# TPCC0_TPCC0 register map
Vendor: Texas Instruments
Peripheral module from a debugger description file (folder AM263).
Registers are 32-bit, read-only, reset 0x0 unless marked. A register's access mark holds for its fields unless they carry their own. Offsets are as the file gives them; lines under a group give offsets from that group; [hi:lo] are bit positions; {n}, {i} and the like mark numbered series; 'fields as' and 'values as' point back to an identical list; <NAME> marks a mode.

## TPCC0_TPCC0
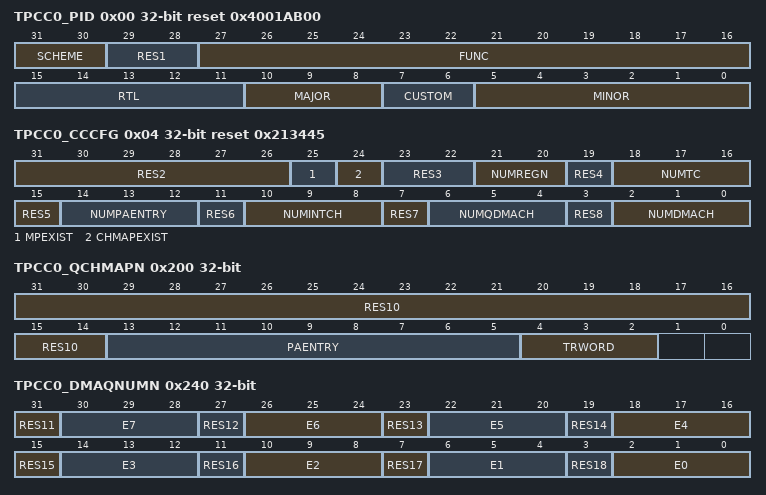
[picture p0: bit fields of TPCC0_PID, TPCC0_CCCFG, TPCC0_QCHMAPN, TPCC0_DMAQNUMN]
0x00 TPCC0_PID reset 0x4001AB00
  [31:30] SCHEME — PID Scheme: Used to distinguish between old ID scheme and current. Spare bit to encode future schemes EDMA uses 'new scheme' indicated with value of 0x1.
  [29:28] RES1 — RESERVE FIELD
  [27:16] FUNC — Function indicates a software compatible module family.
  [15:11] RTL — RTL Version
  [10:8] MAJOR — Major Revision
  [7:6] CUSTOM — Custom revision field: Not used on this version of EDMA.
  [5:0] MINOR — Minor Revision
0x04 TPCC0_CCCFG reset 0x213445
  [31:26] RES2 — RESERVE FIELD
  [25] MPEXIST — Memory Protection Existence MPEXIST = 0 : No memory protection. MPEXIST = 1 : Memory Protection logic included.
  [24] CHMAPEXIST — Channel Mapping Existence CHMAPEXIST = 0 : No Channel mapping. CHMAPEXIST = 1 : Channel mapping logic included.
  [23:22] RES3 — RESERVE FIELD
  [21:20] NUMREGN — Number of MP and Shadow regions
  [35-4n] RES{n} (n=4..8) — RESERVE FIELD
  [18:16] NUMTC — Number of Queues/Number of TCs
  [14:12] NUMPAENTRY — Number of PaRAM entries
  [10:8] NUMINTCH — Number of Interrupt Channels
  [6:4] NUMQDMACH — Number of QDMA Channels
  [2:0] NUMDMACH — Number of DMA Channels
0x200 TPCC0_QCHMAPN access per field
  [31:14] RES10 ro — RESERVE FIELD
  [13:5] PAENTRY rw — PaRAM Entry number for QDMA Channel N.
  [4:2] TRWORD rw — TRWORD points to the specific trigger word of the PaRAM Entry defined by PAENTRY. A write to the trigger word results in a QDMA Event being recognized.
0x240 TPCC0_DMAQNUMN access per field
  [75-4n] RES{n} ro (n=11..18) — RESERVE FIELD
  [4n+2:4n] E{n} rw (n=0..7) — DMA Queue Number for event #{n}
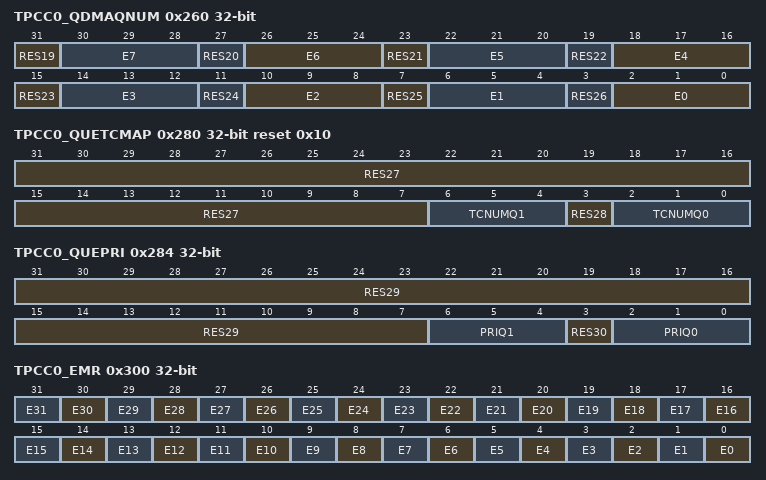
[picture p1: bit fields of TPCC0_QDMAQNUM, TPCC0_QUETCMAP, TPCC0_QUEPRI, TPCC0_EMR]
0x260 TPCC0_QDMAQNUM access per field
  [107-4n] RES{n} ro (n=19..26) — RESERVE FIELD
  [4n+2:4n] E{n} rw (n=0..7) — QDMA Queue Number for event #{n}
0x280 TPCC0_QUETCMAP access per field reset 0x10
  [31:7] RES27 ro — RESERVE FIELD
  [6:4] TCNUMQ1 rw — TC Number for Queue N: Defines the TC number that Event Queue N TRs are written to.
  [3] RES28 ro — RESERVE FIELD
  [2:0] TCNUMQ0 rw — TC Number for Queue N: Defines the TC number that Event Queue N TRs are written to.
0x284 TPCC0_QUEPRI access per field
  [31:7] RES29 ro — RESERVE FIELD
  [6:4] PRIQ1 rw — Priority Level for Queue 1 Dictates the priority level used for the OPTIONS field programmation for Qn TRs. Sets the priority used for TC read and write commands.
  [3] RES30 ro — RESERVE FIELD
  [2:0] PRIQ0 rw — Priority Level for Queue 0 Dictates the priority level used for the OPTIONS field programmation for Qn TRs. Sets the priority used for TC read and write commands.
0x300 TPCC0_EMR
  [n] E{n} (n=0..31) — Event Missed #{n}
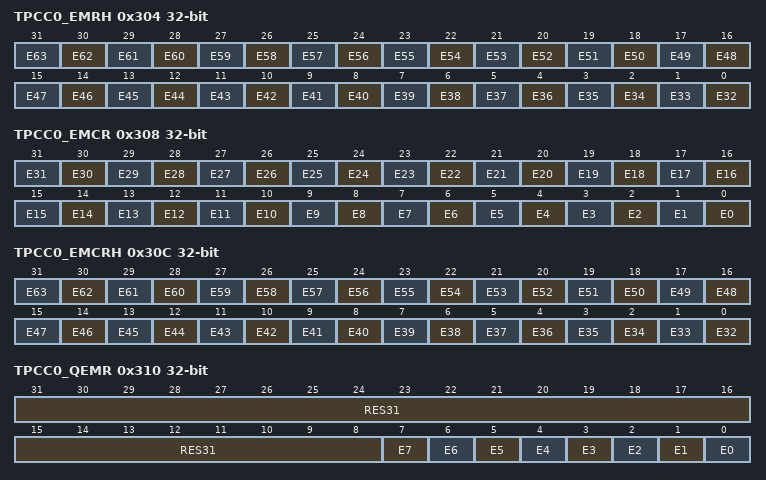
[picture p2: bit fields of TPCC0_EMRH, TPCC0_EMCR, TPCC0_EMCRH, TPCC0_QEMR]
0x304 TPCC0_EMRH
  [n-32] E{n} (n=32..63) — Event Missed #{n}
0x308 TPCC0_EMCR wo
  [n] E{n} (n=0..31) — Event Missed Clear #{n}
0x30C TPCC0_EMCRH wo
  [n-32] E{n} (n=32..63) — Event Missed Clear #{n}
0x310 TPCC0_QEMR
  [31:8] RES31 — RESERVE FIELD
  [n] E{n} (n=0..7) — Event Missed #{n}
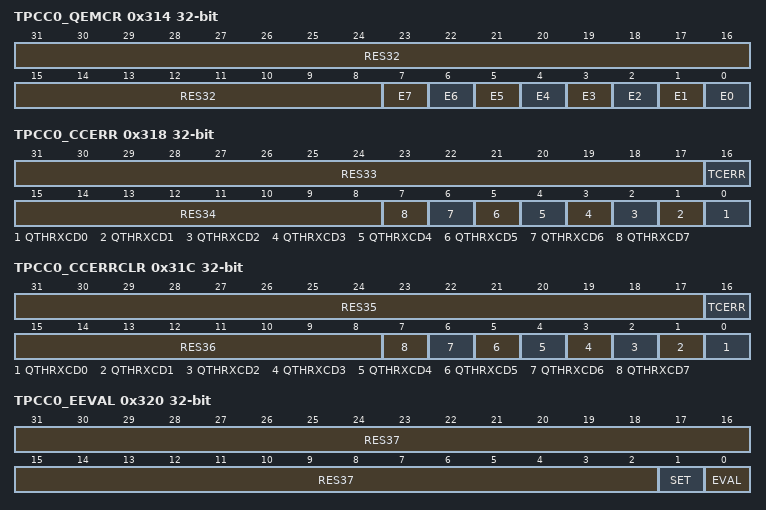
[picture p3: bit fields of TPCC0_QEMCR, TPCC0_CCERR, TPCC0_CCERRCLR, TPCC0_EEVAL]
0x314 TPCC0_QEMCR access per field
  [31:8] RES32 ro — RESERVE FIELD
  [n] E{n} wo (n=0..7) — Event Missed Clear #{n}
0x318 TPCC0_CCERR
  [31:17] RES33 — RESERVE FIELD
  [16] TCERR — Transfer Completion Code Error: TCCERR = 0 : Total number of allowed TCCs outstanding has not been reached. TCCERR = 1 : Total number of allowed TCCs has been reached. TCCERR can be cleared by writing a '1' to corresponding bit in CCERRCLR register. If any bit in the CCERR register is set (and all errors were previously clear) then an error will be signaled with TPCC error interrupt.
  [15:8] RES34 — RESERVE FIELD
  [n] QTHRXCD{n} (n=0..7) — Queue Threshold Error for Q{n}: QTHRXCD{n} = 0 : Watermark/threshold has not been exceeded. QTHRXCD{n} = 1 : Watermark/threshold has been exceeded. CCERR.QTHRXCD{n} can be cleared by writing a '1' to corresponding bit in CCERRCLR register. If any bit in the CCERR register is set (and all errors (including EMR/QEMR) were previously clear) then an error will be signaled with the TPCC error interrupt.
0x31C TPCC0_CCERRCLR access per field
  [31:17] RES35 ro — RESERVE FIELD
  [16] TCERR wo — Clear Error for CCERR.TCERR: Write of '1' clears the value of CCERR bit N. Writes of '0' have no affect.
  [15:8] RES36 ro — RESERVE FIELD
  [n] QTHRXCD{n} wo (n=0..7) — Clear error for CCERR.QTHRXCD{n}: Write of '1' clears the values of QSTAT{n}.WM QSTAT{n}.THRXCD CCERR.QTHRXCD{n} Writes of '0' have no affect.
0x320 TPCC0_EEVAL access per field
  [31:2] RES37 ro — RESERVE FIELD
  [1] SET wo — Error Interrupt Set: CPU write of '1' to the SET bit causes the TPCC error interrupt to be pulsed regardless of state of EMR/EMRH QEMR or CCERR. CPU write of '0' has no effect.
  [0] EVAL wo — Error Interrupt Evaluate: CPU write of '1' to the EVAL bit causes the TPCC error interrupt to be pulsed if any errors have not been cleared in the EMR/EMRH QEMR or CCERR registers. CPU write of '0' has no effect.
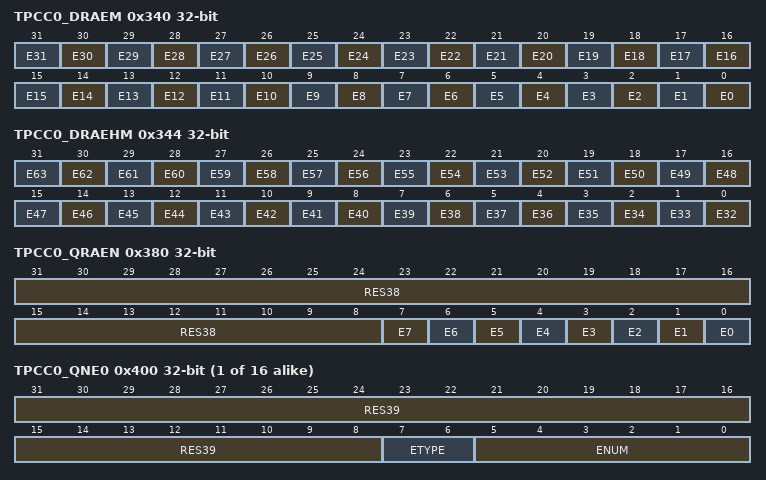
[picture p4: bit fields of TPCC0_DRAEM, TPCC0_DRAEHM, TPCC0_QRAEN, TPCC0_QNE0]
0x340 TPCC0_DRAEM rw
  [n] E{n} (n=0..31) — DMA Region Access enable for Region M bit #{n}
0x344 TPCC0_DRAEHM rw
  [n-32] E{n} (n=32..63) — DMA Region Access enable for Region M bit #{n}
0x380 TPCC0_QRAEN access per field
  [31:8] RES38 ro — RESERVE FIELD
  [n] E{n} rw (n=0..7) — QDMA Region Access enable for Region M bit #{n}
{0x400+4i} TPCC0_QNE{i} (i=0..15)
  [31:8] RES{i+39} — RESERVE FIELD
  [7:6] ETYPE — Event Type: Specifies the specific Event Type for the given entry in the Event Queue.
  [5:0] ENUM — Event Number: Specifies the specific Event Number for the given entry in the Event Queue. For DMA Channel events (ER/ESR/CER) ENUM will range between 0 and NUM_DMACH (up to 63). For QDMA Channel events (QER) ENUM will range between 0 and NUM_QDMACH (up to 7).
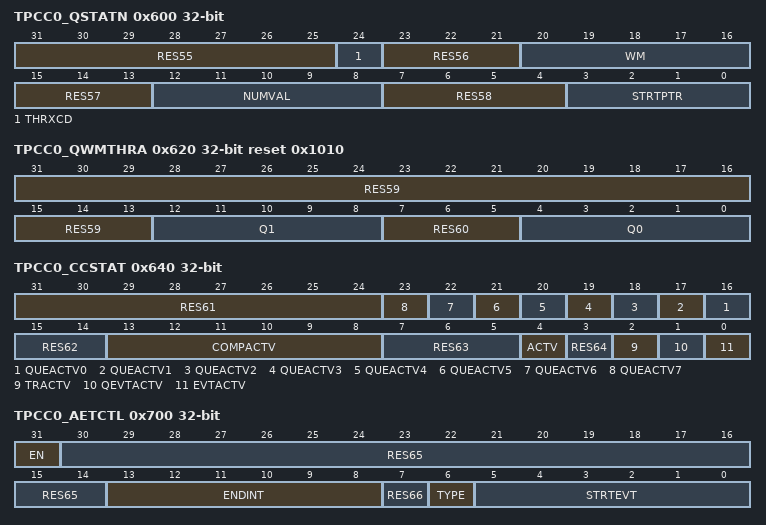
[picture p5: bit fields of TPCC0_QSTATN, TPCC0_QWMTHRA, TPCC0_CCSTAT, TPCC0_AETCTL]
0x600 TPCC0_QSTATN
  [31:25] RES55 — RESERVE FIELD
  [24] THRXCD — Threshold Exceeded: THRXCD = 0 : Threshold specified by QWMTHR(A B).Qn has not been exceeded. THRXCD = 1 : Threshold specified by QWMTHR(A B).Qn has been exceeded. QSTATn.THRXCD is cleared via CCERR.WMCLRn bit.
  [23:21] RES56 — RESERVE FIELD
  [20:16] WM — Watermark for Maximum Queue Usage: Watermark tracks the most entries that have been in QueueN since reset or since the last time that the watermark (WM) was cleared. QSTATn.WM is cleared via CCERR.WMCLRn bit. Legal values = 0x0 (empty) to 0x10 (full)
  [15:13] RES57 — RESERVE FIELD
  [12:8] NUMVAL — Number of Valid Entries in QueueN: Represents the total number of entries residing in the Queue Manager FIFO at a given instant. Always enabled. Legal values = 0x0 (empty) to 0x10 (full)
  [7:4] RES58 — RESERVE FIELD
  [3:0] STRTPTR — Start Pointer: Represents the offset to the head entry of QueueN in units of entries. Always enabled. Legal values = 0x0 (0th entry) to 0xF (15th entry)
0x620 TPCC0_QWMTHRA access per field reset 0x1010
  [31:13] RES59 ro — RESERVE FIELD
  [12:8] Q1 rw — Queue Threshold for Q1 value
  [7:5] RES60 ro — RESERVE FIELD
  [4:0] Q0 rw — Queue Threshold for Q0 value
0x640 TPCC0_CCSTAT
  [31:24] RES61 — RESERVE FIELD
  [n+16] QUEACTV{n} (n=0..7) — Queue {n} Active QUEACTV{n} = 0 : No Evts are queued in Q{n}. QUEACTV{n} = 1 : At least one TR is queued in Q{n}.
  [15:14] RES62 — RESERVE FIELD
  [13:8] COMPACTV — Completion Request Active: Counter that tracks the total number of completion requests submitted to the TC. The counter increments when a TR is submitted with TCINTEN or TCCHEN set to '1'. The counter decrements for every valid completion code received from any of the external TCs. The CC will not service new TRs if COMPACTV count is already at the limit. COMPACTV = 0 : No completion requests outstanding. COMPACTV = 1: Total of '1' completion request outstanding. ... COMPACTV = 63 : Total of 63 completion requests are outstanding. No additional TRs will be submitted until count is less than 63.
  [7:5] RES63 — RESERVE FIELD
  [4] ACTV — Channel Controller Active: Channel Controller Active is a logical-OR of each of the ACTV signals. The ACTV bit must remain high through the life of a TR. ACTV = 0 : Channel is idle. ACTV = 1 : Channel is busy.
  [3] RES64 — RESERVE FIELD
  [2] TRACTV — Transfer Request Active: TRACTV = 0 : Transfer Request processing/submission logic is inactive. TRACTV = 1 : Transfer Request processing/submission logic is active.
  [1] QEVTACTV — QDMA Event Active: QEVTACTV = 0 : No enabled QDMA Events are active within the CC. QEVTACTV = 1 : At least one enabled DMA Event (ER & EER ESR CER) is active within the CC.
  [0] EVTACTV — DMA Event Active: EVTACTV = 0 : No enabled DMA Events are active within the CC. EVTACTV = 1 : At least one enabled DMA Event (ER & EER ESR CER) is active within the CC.
0x700 TPCC0_AETCTL access per field
  [31] EN rw — AET Enable: EN = 0 : AET event generation is disabled. EN = 1 : AET event generation is enabled.
  [30:14] RES65 ro — RESERVE FIELD
  [13:8] ENDINT rw — AET End Interrupt: Dictates the completion interrupt number that will force the tpcc_aet signal to be deasserted (low)
  [7] RES66 ro — RESERVE FIELD
  [6] TYPE rw — AET Event Type: TYPE = 0 : Event specified by STARTEVT applies to DMA Events (set by ER ESR or CER) TYPE = 1 : Event specified by STARTEVT applies to QDMA Events
  [5:0] STRTEVT rw — AET Start Event: Dictates the Event Number that will force the tpcc_aet signal to be asserted (high)
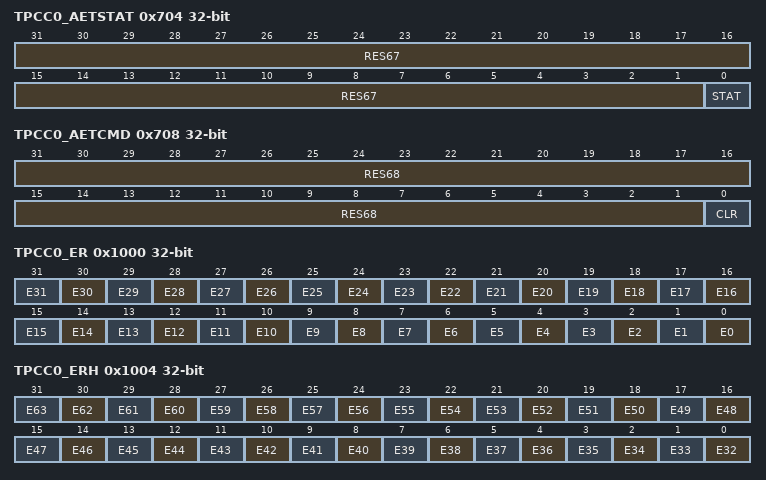
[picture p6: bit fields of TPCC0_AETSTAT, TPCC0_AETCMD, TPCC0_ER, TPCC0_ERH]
0x704 TPCC0_AETSTAT
  [31:1] RES67 — RESERVE FIELD
  [0] STAT — AET Status: AETSTAT = 0 : tpcc_aet is currently low. AETSTAT = 1 : tpcc_aet is currently high.
0x708 TPCC0_AETCMD access per field
  [31:1] RES68 ro — RESERVE FIELD
  [0] CLR wo — AET Clear command: CPU write of '1' to the CLR bit causes the tpcc_aet output signal and AETSTAT.STAT register to be cleared. CPU write of '0' has no effect..
0x1000 TPCC0_ER
  [n] E{n} (n=0..31) — Event #{n}
0x1004 TPCC0_ERH
  [n-32] E{n} (n=32..63) — Event #{n}
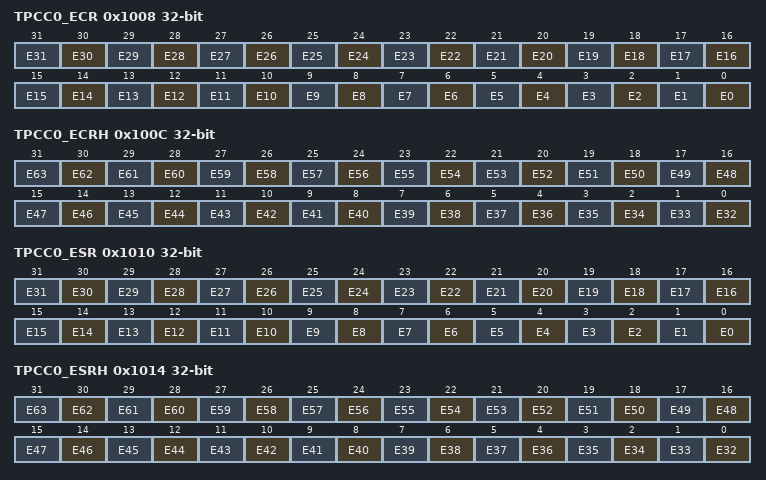
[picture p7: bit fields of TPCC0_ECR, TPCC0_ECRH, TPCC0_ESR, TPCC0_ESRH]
0x1008 TPCC0_ECR wo
  [n] E{n} (n=0..31) — Event #{n}
0x100C TPCC0_ECRH wo
  [n-32] E{n} (n=32..63) — Event #{n}
0x1010 TPCC0_ESR wo
  [n] E{n} (n=0..31) — Event #{n}
0x1014 TPCC0_ESRH wo
  [n-32] E{n} (n=32..63) — Event #{n}
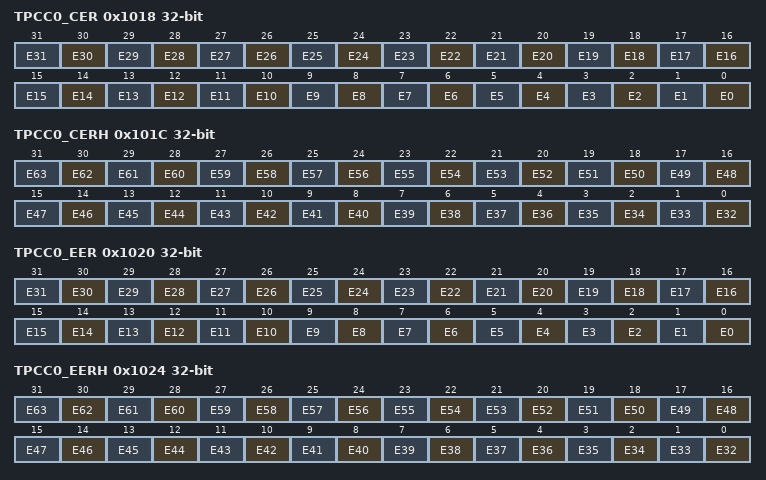
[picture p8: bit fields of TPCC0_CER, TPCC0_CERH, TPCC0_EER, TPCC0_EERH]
0x1018 TPCC0_CER
  [n] E{n} (n=0..31) — Event #{n}
0x101C TPCC0_CERH
  [n-32] E{n} (n=32..63) — Event #{n}
0x1020 TPCC0_EER
  [n] E{n} (n=0..31) — Event #{n}
0x1024 TPCC0_EERH
  [n-32] E{n} (n=32..63) — Event #{n}
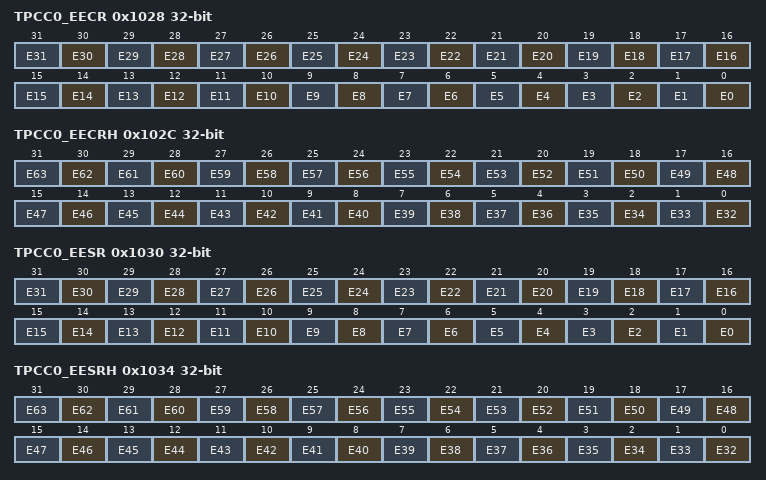
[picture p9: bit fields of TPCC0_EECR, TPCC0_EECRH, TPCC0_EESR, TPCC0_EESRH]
0x1028 TPCC0_EECR wo
  [n] E{n} (n=0..31) — Event #{n}
0x102C TPCC0_EECRH wo
  [n-32] E{n} (n=32..63) — Event #{n}
0x1030 TPCC0_EESR wo
  [n] E{n} (n=0..31) — Event #{n}
0x1034 TPCC0_EESRH wo
  [n-32] E{n} (n=32..63) — Event #{n}
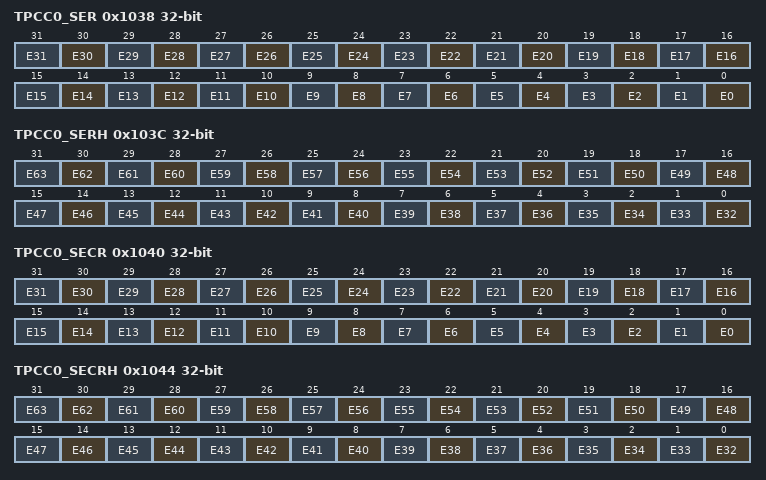
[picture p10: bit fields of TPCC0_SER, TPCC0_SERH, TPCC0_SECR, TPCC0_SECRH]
0x1038 TPCC0_SER
  [n] E{n} (n=0..31) — Event #{n}
0x103C TPCC0_SERH
  [n-32] E{n} (n=32..63) — Event #{n}
0x1040 TPCC0_SECR wo
  [n] E{n} (n=0..31) — Event #{n}
0x1044 TPCC0_SECRH wo
  [n-32] E{n} (n=32..63) — Event #{n}
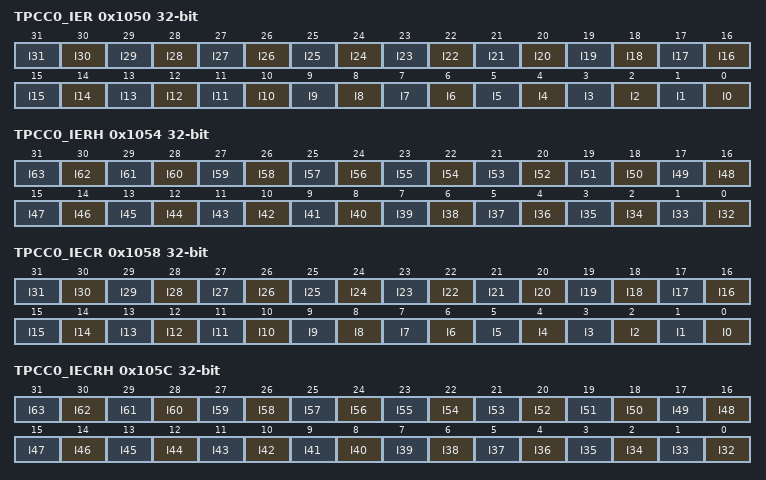
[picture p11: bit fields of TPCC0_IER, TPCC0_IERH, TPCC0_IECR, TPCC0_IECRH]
0x1050 TPCC0_IER
  [n] I{n} (n=0..31) — Interrupt associated with TCC #{n}
0x1054 TPCC0_IERH
  [n-32] I{n} (n=32..63) — Interrupt associated with TCC #{n}
0x1058 TPCC0_IECR wo
  [n] I{n} (n=0..31) — Interrupt associated with TCC #{n}
0x105C TPCC0_IECRH wo
  [n-32] I{n} (n=32..63) — Interrupt associated with TCC #{n}
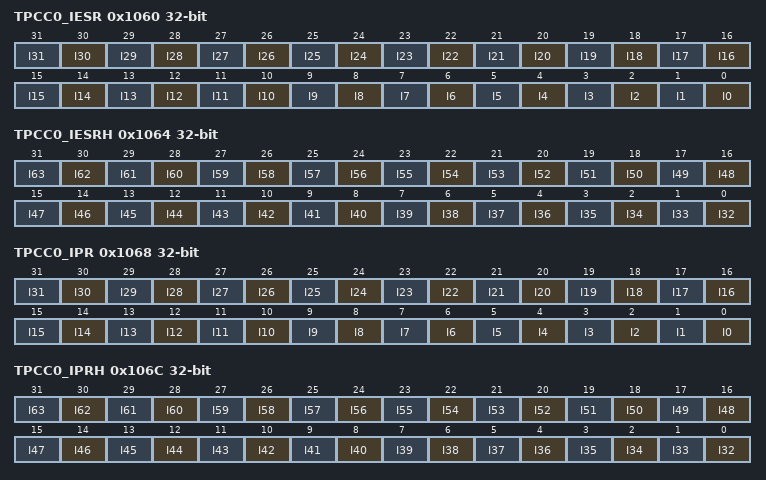
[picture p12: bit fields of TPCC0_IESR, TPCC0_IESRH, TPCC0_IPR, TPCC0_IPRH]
0x1060 TPCC0_IESR wo
  [n] I{n} (n=0..31) — Interrupt associated with TCC #{n}
0x1064 TPCC0_IESRH wo
  [n-32] I{n} (n=32..63) — Interrupt associated with TCC #{n}
0x1068 TPCC0_IPR
  [n] I{n} (n=0..31) — Interrupt associated with TCC #{n}
0x106C TPCC0_IPRH
  [n-32] I{n} (n=32..63) — Interrupt associated with TCC #{n}
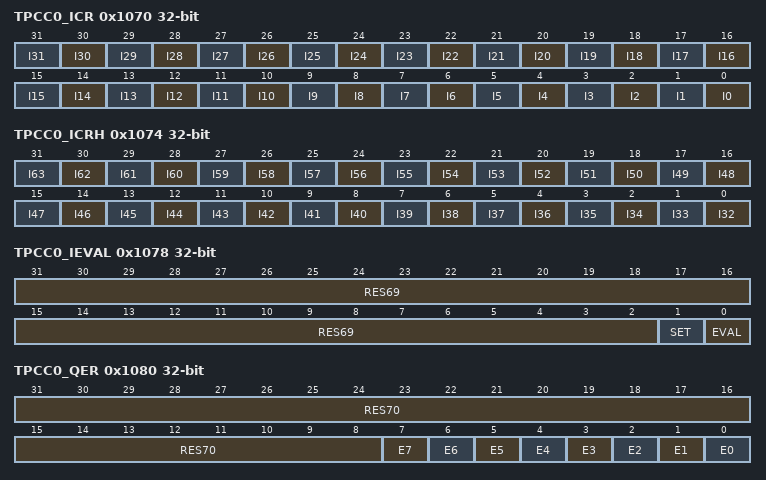
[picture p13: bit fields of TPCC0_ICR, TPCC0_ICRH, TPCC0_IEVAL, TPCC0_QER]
0x1070 TPCC0_ICR wo
  [n] I{n} (n=0..31) — Interrupt associated with TCC #{n}
0x1074 TPCC0_ICRH wo
  [n-32] I{n} (n=32..63) — Interrupt associated with TCC #{n}
0x1078 TPCC0_IEVAL access per field
  [31:2] RES69 ro — RESERVE FIELD
  [1] SET wo — Interrupt Set: CPU write of '1' to the SETn bit causes the tpcc_intN output signal to be pulsed egardless of state of interrupts enable (IERn) and status (IPRn). CPU write of '0' has no effect.
  [0] EVAL wo — Interrupt Evaluate: CPU write of '1' to the EVALn bit causes the tpcc_intN output signal to be pulsed if any enabled interrupts (IERn) are still pending (IPRn). CPU write of '0' has no effect..
0x1080 TPCC0_QER
  [31:8] RES70 — RESERVE FIELD
  [n] E{n} (n=0..7) — Event #{n}
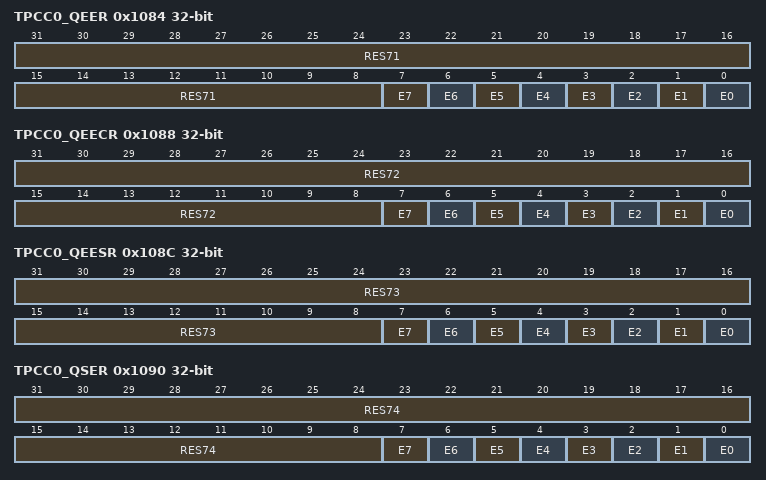
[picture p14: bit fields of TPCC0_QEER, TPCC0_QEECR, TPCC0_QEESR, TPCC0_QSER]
0x1084 TPCC0_QEER
  [31:8] RES71 — RESERVE FIELD
  [n] E{n} (n=0..7) — Event #{n}
0x1088 TPCC0_QEECR access per field
  [31:8] RES72 ro — RESERVE FIELD
  [n] E{n} wo (n=0..7) — Event #{n}
0x108C TPCC0_QEESR access per field
  [31:8] RES73 ro — RESERVE FIELD
  [n] E{n} wo (n=0..7) — Event #{n}
0x1090 TPCC0_QSER
  [31:8] RES74 — RESERVE FIELD
  [n] E{n} (n=0..7) — Event #{n}
0x1094 TPCC0_QSECR access per field
  [31:8] RES75 ro — RESERVE FIELD
  [n] E{n} wo (n=0..7) — Event #{n}
0x2000 TPCC0_ER_RN
  [n] E{n} (n=0..31) — Event #{n}
0x2004 TPCC0_ERH_RN
  [n-32] E{n} (n=32..63) — Event #{n}
0x2008 TPCC0_ECR_RN wo
  [n] E{n} (n=0..31) — Event #{n}
0x200C TPCC0_ECRH_RN wo
  [n-32] E{n} (n=32..63) — Event #{n}
0x2010 TPCC0_ESR_RN wo
  [n] E{n} (n=0..31) — Event #{n}
0x2014 TPCC0_ESRH_RN wo
  [n-32] E{n} (n=32..63) — Event #{n}
0x2018 TPCC0_CER_RN
  [n] E{n} (n=0..31) — Event #{n}
0x201C TPCC0_CERH_RN
  [n-32] E{n} (n=32..63) — Event #{n}
0x2020 TPCC0_EER_RN
  [n] E{n} (n=0..31) — Event #{n}
0x2024 TPCC0_EERH_RN
  [n-32] E{n} (n=32..63) — Event #{n}
0x2028 TPCC0_EECR_RN wo
  [n] E{n} (n=0..31) — Event #{n}
0x202C TPCC0_EECRH_RN wo
  [n-32] E{n} (n=32..63) — Event #{n}
0x2030 TPCC0_EESR_RN wo
  [n] E{n} (n=0..31) — Event #{n}
0x2034 TPCC0_EESRH_RN wo
  [n-32] E{n} (n=32..63) — Event #{n}
0x2038 TPCC0_SER_RN
  [n] E{n} (n=0..31) — Event #{n}
0x203C TPCC0_SERH_RN
  [n-32] E{n} (n=32..63) — Event #{n}
0x2040 TPCC0_SECR_RN wo
  [n] E{n} (n=0..31) — Event #{n}
0x2044 TPCC0_SECRH_RN wo
  [n-32] E{n} (n=32..63) — Event #{n}
0x2050 TPCC0_IER_RN
  [n] I{n} (n=0..31) — Interrupt associated with TCC #{n}
0x2054 TPCC0_IERH_RN
  [n-32] I{n} (n=32..63) — Interrupt associated with TCC #{n}
0x2058 TPCC0_IECR_RN wo
  [n] I{n} (n=0..31) — Interrupt associated with TCC #{n}
0x205C TPCC0_IECRH_RN wo
  [n-32] I{n} (n=32..63) — Interrupt associated with TCC #{n}
0x2060 TPCC0_IESR_RN wo
  [n] I{n} (n=0..31) — Interrupt associated with TCC #{n}
0x2064 TPCC0_IESRH_RN wo
  [n-32] I{n} (n=32..63) — Interrupt associated with TCC #{n}
0x2068 TPCC0_IPR_RN
  [n] I{n} (n=0..31) — Interrupt associated with TCC #{n}
0x206C TPCC0_IPRH_RN
  [n-32] I{n} (n=32..63) — Interrupt associated with TCC #{n}
0x2070 TPCC0_ICR_RN wo
  [n] I{n} (n=0..31) — Interrupt associated with TCC #{n}
0x2074 TPCC0_ICRH_RN wo
  [n-32] I{n} (n=32..63) — Interrupt associated with TCC #{n}
0x2078 TPCC0_IEVAL_RN access per field
  [31:2] RES76 ro — RESERVE FIELD
  [1] SET wo — Interrupt Set: CPU write of '1' to the SETn bit causes the tpcc_intN output signal to be pulsed egardless of state of interrupts enable (IERn) and status (IPRn). CPU write of '0' has no effect.
  [0] EVAL wo — Interrupt Evaluate: CPU write of '1' to the EVALn bit causes the tpcc_intN output signal to be pulsed if any enabled interrupts (IERn) are still pending (IPRn). CPU write of '0' has no effect..
0x2080 TPCC0_QER_RN
  [31:8] RES77 — RESERVE FIELD
  [n] E{n} (n=0..7) — Event #{n}
0x2084 TPCC0_QEER_RN
  [31:8] RES78 — RESERVE FIELD
  [n] E{n} (n=0..7) — Event #{n}
0x2088 TPCC0_QEECR_RN access per field
  [31:8] RES79 ro — RESERVE FIELD
  [n] E{n} wo (n=0..7) — Event #{n}
0x208C TPCC0_QEESR_RN access per field
  [31:8] RES80 ro — RESERVE FIELD
  [n] E{n} wo (n=0..7) — Event #{n}
0x2090 TPCC0_QSER_RN
  [31:8] RES81 — RESERVE FIELD
  [n] E{n} (n=0..7) — Event #{n}
0x2094 TPCC0_QSECR_RN access per field
  [31:8] RES82 ro — RESERVE FIELD
  [n] E{n} wo (n=0..7) — Event #{n}
0x4000 TPCC0_OPT access per field
  [31] PRIV ro — Privilege level: privilege level (supervisor vs. user) for the host/cpu/dma that programmed this PaRAM Entry. Value is set with the vbus priv value when any part of the PaRAM Entry is written. Not writeable via vbus wdata bus. Is readable via VBus rdata bus. PRIV = 0 : User level privilege PRIV = 1 : Supervisor level privilege
  [30:28] RES83 ro — RESERVE FIELD
  [27:24] PRIVID ro — Privilege ID: Privilege ID for the external host/cpu/dma that programmed this PaRAM Entry. This value is set with the vbus privid value when any part of the PaRAM Entry is written. Not writeable via vbus wdata bus. Is readable via VBus rdata bus.
  [23] ITCCHEN rw — Intermediate transfer completion chaining enable: 0: Intermediate transfer complete chaining is disabled. 1: Intermediate transfer complete chaining is enabled.
  [22] TCCHEN rw — Transfer complete chaining enable: 0: Transfer complete chaining is disabled. 1: Transfer complete chaining is enabled.
  [21] ITCINTEN rw — Intermediate transfer completion interrupt enable: 0: Intermediate transfer complete interrupt is disabled. 1: Intermediate transfer complete interrupt is enabled (corresponding IER[TCC] bit must be set to 1 to generate interrupt)
  [20] TCINTEN rw — Transfer complete interrupt enable: 0: Transfer complete interrupt is disabled. 1: Transfer complete interrupt is enabled (corresponding IER[TCC] bit must be set to 1 to generate interrupt)
  [19] WIMODE rw — Backward compatibility mode: 0: Normal operation 1 : WI Backwards Compatibility mode forces BCNT to be adjusted by '1' upon TR submission (0 means 1 1 means 2 ... ) and forces ACNT to be treated as a word-count (left shifted by 2 by hardware to create byte cnt for TR submission)
  [18] RES84 ro — RESERVE FIELD
  [17:12] TCC rw — Transfer Complete Code: The 6-bit code is used to set the relevant bit in CER (bit CER[TCC]) for chaining or in IER (bit IER[TCC]) for interrupts.
  [11] TCCMODE rw — Transfer complete code mode: Indicates the point at which a transfer is considered completed. Applies to both chaining and interrupt. 0: Normal Completion A transfer is considered completed after the transfer parameters are returned to the CC from the TC (which was returned from the peripheral). 1: Early Completion A transfer is considered completed after the CC submits a TR to the TC. CC generates completion code internally .
  [10:8] FWID rw — FIFO width: Applies if either SAM or DAM is set to FIFO mode. Pass-thru to TC.
  [7:4] RES85 ro — RESERVE FIELD
  [3] STATIC rw — Static Entry: 0: Entry is updated as normal 1: Entry is static Count and Address updates are not updated after TRP is submitted. Linking is not performed.
  [2] SYNCDIM rw — Transfer Synchronization Dimension: 0: A-Sync Each event triggers the transfer of ACNT elements. 1: AB-Sync Each event triggers the transfer of BCNT arrays of ACNT elements
  [1] DAM rw — Destination Address Mode: Destination Address Mode within an array. Pass-thru to TC. 0: INCR Dst addressing within an array increments. Dst is not a FIFO. 1: FIFO Dst addressing within an array wraps around upon reaching FIFO width.
  [0] SAM rw — Source Address Mode: Source Address Mode within an array. Pass-thru to TC. 0: INCR Src addressing within an array increments. Source is not a FIFO. 1: FIFO Src addressing within an array wraps around upon reaching FIFO width.
0x4004 TPCC0_SRC rw
  [31:0] SRC — Source Address: The 32-bit source address parameters specify the starting byte address of the source . If SAM is set to FIFO mode then the user should program the Source address to be aligned to the value specified by the OPT.FWID field. No errors are recognized here but TC will assert error if this is not true.
0x4008 TPCC0_ABCNT rw
  [31:16] BCNT — BCNT : Count for 2nd Dimension: BCNT is a 16-bit unsigned value that specifies the number of arrays of length ACNT. For normal operation valid values for BCNT can be anywhere between 1 and 65535. Therefore the maximum number of arrays in a frame is 65535 (64K-1 arrays). BCNT=1 means 1 array in the frame and BCNT=0 means 0 arrays in the frame. In normal mode a BCNT of '0' is considered as either a Null or Dummy transfer. A Dummy or Null transfer will generate a Completion code depending on the settings of the completion bit fields of the OPT field. If the OPT.WIMODE bit is set then the programmed BCNT value will be incremented by '1' before submission to TC. I.e. 0 means 1 1 means 2 2 means 3 ...
  [15:0] ACNT — ACNT : number of bytes in 1st dimension: ACNT represents the number of bytes within the first dimension of a transfer. ACNT is a 16-bit unsigned value with valid values between 0 and 65535. Therefore the maximum number of bytes in an array is 65535 bytes (64K-1 bytes). ACNT must be greater than or equal to '1' for a TR to be submitted to TC. An ACNT of '0' is considered as either a null or dummy transfer. A Dummy or Null transfer will generate a Completion code depending on the settings of the completion bit fields of the OPT field. If the OPT.WIMODE bit is set then the ACNT field represents a word count. The CC must internally multiply by 4 to translate the word count to a byte count prior to submission to the TC. The 2 MSBs of the 16-bit ACNT are reserved and should always be written as 'b00 by the user. If user writes a value other than 0 it will still be treated as 0 since the multiply-by-4 operation (to translate between a word count and a byte count) will dropthe 2 msbits. For dummy and null transfer definition the ACNT definition will disregard the 2 msbits. I.e. a programmed ACNT value of 0x8000 in WI-mode will be treated as 0 byte transfer resulting in null or dummy operation dependent on the state of BCNT and CCNT.
0x400C TPCC0_DST rw
  [31:0] DST — Destination Address: The 32-bit destination address parameters specify the starting byte address of the destination. If DAM is set to FIFO mode then the user should program the Destination address to be aligned to the value specified by the OPT.FWID field. No errors are recognized here but TC will assert error if this is not true.
0x4010 TPCC0_BIDX rw
  [31:16] DBIDX — Destination 2nd Dimension Index: DBIDX is a 16-bit signed value (2's complement) used for destination address modification in between each array in the 2nd dimension. It is a signed value between -32768 and 32767. It provides a byte address offset from the beginning of the destination array to the beginning of the next destination array within the current frame. It applies to both A-Sync and AB-Sync transfers.
  [15:0] SBIDX — Source 2nd Dimension Index: SBIDX is a 16-bit signed value (2's complement) used for source address modification in between each array in the 2nd dimension. It is a signed value between -32768 and 32767. It provides a byte address offset from the beginning of the source array to the beginning of the next source array. It applies to both A-sync and AB-sync transfers.
0x4014 TPCC0_LNK rw
  [31:16] BCNTRLD — BCNT Reload: BCNTRLD is a 16-bit unsigned value used to reload the BCNT field once the last array in the 2nd dimension is transferred. This field is only used for A-Sync'ed transfers. In this case the CC decrements the BCNT value by one on each TR submission. When BCNT (conceptually) reaches zero then the CC decrements CCNT and uses the BCNTRLD value to reinitialize the BCNT value. For AB-synchronized transfers the CC submits the BCNT in the TR and therefore the TC is responsible to keep track of BCNT not thus BCNTRLD is a don't care field.
  [15:0] LINK — Link Address: The CC provides a mechanism to reload the current PaRAM Entry upon its natural termination (i.e. after count fields are decremented to '0') with a new PaRAM Entry. This is called 'linking'. The 16-bit parameter LINK specifies the byte address offset in the PaRAM from which the CC loads/reloads the next PaRAM entry in the link. The CC should disregard the value in the upper 2 bits of the LINK field as well as the lower 5-bits of the LINK field. The upper two bits are ignored such that the user can program either the 'literal' byte address of the LINK parameter or the 'PaRAM base-relative' address of the link field. Therefore if the user uses the literal address with a range from 0x4000 to 0x7FFF it will be treated as a PaRAM-base-relative value of 0x0000 to 0x3FFF. The lower-5 bits are ignored and treated as 'b00000 thereby guaranteeing that all Link pointers point to a 32-byte aligned PaRAM entry. In the latter case (5-lsbs) behavior is undefined forthe user (i.e. don't have to test it). In the former case (2 msbs) user should be able to take advantage of this feature (i.e. do have to test it). If a Link Update is requested to a PaRAM address that is beyond the actual range of implemented PaRAM then the Link will be treated as a Null Linkand all 0s plus 0xFFFF will be written to the current entry location. A LINK value of 0xFFFF is referred to as a NULL link which should cause the CC to write 0x0 to all entries of the current PaRAM Entry except for the LINK field which is set to 0xFFFF. The Priv/Privid/Secure state is overwritten to 0x0 when linking. MSBs and LSBS should not be masked when comparing against the 0xFFFF value. I.e. a value of 0x3FFE is a non-NULL PaRAM link field.
0x4018 TPCC0_CIDX rw
  [31:16] DCIDX — Destination Frame Index: DCIDX is a 16-bit signed value (2's complement) used for destination address modification for the 3rd dimension. It is a signed value between -32768 and 32767. It provides a byte address offset from the beginning of the current array (pointed to by DST address) to the beginning of the first destination array in the next frame. It applies to both A-sync and AB-sync transfers. Note that when DCIDX is applied the current array in an A-sync transfer is the last array in the frame while the current array in a ABsync transfer is the first array in the frame.
  [15:0] SCIDX — Source Frame Index: SCIDX is a 16-bit signed value (2's complement) used for source address modification for the 3rd dimension. It is a signed value between -32768 and 32767. It provides a byte address offset from the beginning of the current array (pointed to by SRC address) to the beginning of the first source array in the next frame. It applies to both A-sync and AB-sync transfers. Note that when SCIDX is applied the current array in an A-sync transfer is the last array in the frame while the current array in a AB-sync transfer is the first array in the frame.
0x401C TPCC0_CCNT access per field
  [31:16] RES86 ro — RESERVE FIELD
  [15:0] CCNT rw — CCNT : Count for 3rd Dimension: CCNT is a 16-bit unsigned value that specifies the number of frames in a block. Valid values for CCNT can be anywhere between 1 and 65535. Therefore the maximum number of frames in a block is 65535 (64K-1 frames). CCNT of '1' means '1' frame in the block and CCNT of '0' means '0' frames in the block. A CCNT value of '0' is considered as either a null or dummy transfer. A Dummy or Null transfer will generate a Completion code depending on the settings of the completion bit fields of the OPT field. WIMODE has no affect on CCNT operation.
